# N32H7xx register map
Vendor: Nationstech Ltd.; File version: 1.0
CPU: CM7 r1p1, little endian, MPU, FPU, 4 interrupt priority bits
Registers are 32-bit, read-write, reset 0x0 unless marked. A register's access mark holds for its fields unless they carry their own. Offsets are from the block's base; [hi:lo] are bit positions; {n}, {i} and the like mark numbered series; 'fields as' and 'values as' point back to an identical list.

## MDMA — MDMA controller
Base 0x51102000
0x00 MDMA_ID ro
  [31:0] NBR
0x08 MDMA_VERSION ro reset 0x3230302A
  [31:0] NBR
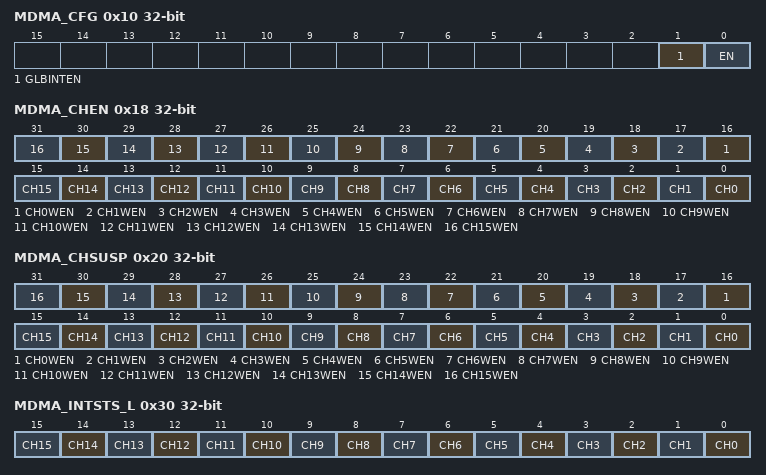
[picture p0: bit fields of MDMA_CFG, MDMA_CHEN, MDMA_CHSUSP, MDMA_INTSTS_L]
0x10 MDMA_CFG
  [1] GLBINTEN, [0] EN
0x18 MDMA_CHEN
  [n+16] CH{n}WEN wo (n=0..15), [n] CH{n} (n=0..15)
0x20 MDMA_CHSUSP
  [n+16] CH{n}WEN wo (n=0..15), [n] CH{n} (n=0..15)
0x30 MDMA_INTSTS_L ro
  [n] CH{n} (n=0..15)
0x34 MDMA_INTSTS_H ro
  [0] COMREG
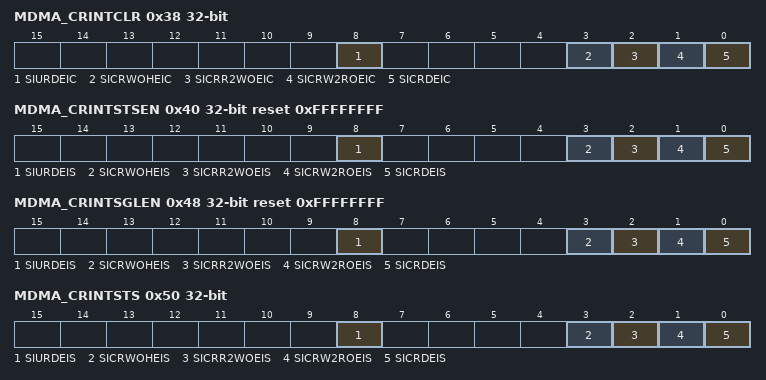
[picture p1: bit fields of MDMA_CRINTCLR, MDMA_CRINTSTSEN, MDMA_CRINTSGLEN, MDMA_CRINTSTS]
0x38 MDMA_CRINTCLR wo
  [8] SIURDEIC, [3] SICRWOHEIC, [2] SICRR2WOEIC, [1] SICRW2ROEIC, [0] SICRDEIC
0x40 MDMA_CRINTSTSEN reset 0xFFFFFFFF
  [8] SIURDEIS, [3] SICRWOHEIS, [2] SICRR2WOEIS, [1] SICRW2ROEIS, [0] SICRDEIS
0x48 MDMA_CRINTSGLEN reset 0xFFFFFFFF
  fields as MDMA_CRINTSTSEN
0x50 MDMA_CRINTSTS ro
  fields as MDMA_CRINTSTSEN
0x58 MDMA_SWRST
  [0] RSTREQ
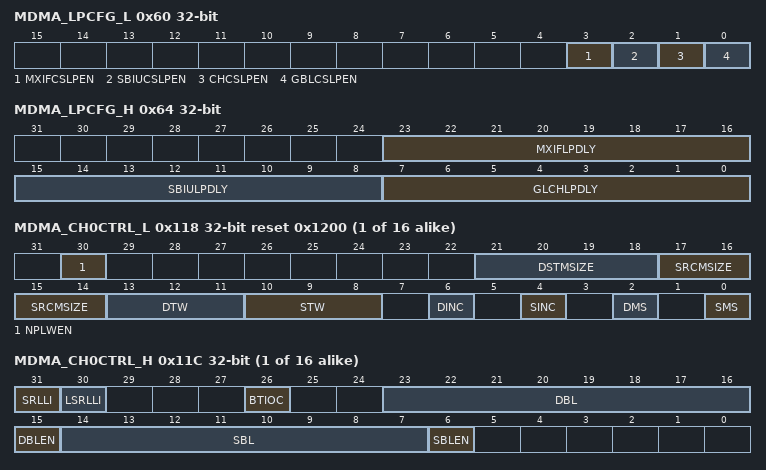
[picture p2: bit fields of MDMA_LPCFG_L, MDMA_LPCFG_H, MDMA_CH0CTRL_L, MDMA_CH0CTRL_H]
0x60 MDMA_LPCFG_L
  [3] MXIFCSLPEN, [2] SBIUCSLPEN, [1] CHCSLPEN, [0] GBLCSLPEN
0x64 MDMA_LPCFG_H
  [23:16] MXIFLPDLY, [15:8] SBIULPDLY, [7:0] GLCHLPDLY
{0x100+0x100*i} MDMA_CH{i}SA_L (i=0..15)
  [31:0] ADDR
{0x104+0x100*i} MDMA_CH{i}SA_H (i=0..15)
  [31:0] ADDR
{0x108+0x100*i} MDMA_CH{i}DA_L (i=0..15)
  [31:0] ADDR
{0x10C+0x100*i} MDMA_CH{i}DA_H (i=0..15)
  [31:0] ADDR
{0x110+0x100*i} MDMA_CH{i}BTS (i=0..15)
  [21:0] NUM
{0x118+0x100*i} MDMA_CH{i}CTRL_L reset 0x1200 (i=0..15)
  [30] NPLWEN, [21:18] DSTMSIZE, [17:14] SRCMSIZE, [13:11] DTW, [10:8] STW, [6] DINC, [4] SINC, [2] DMS, [0] SMS
{0x11C+0x100*i} MDMA_CH{i}CTRL_H (i=0..15)
  [31] SRLLI, [30] LSRLLI, [26] BTIOC, [23:16] DBL, [15] DBLEN, [14:7] SBL, [6] SBLEN
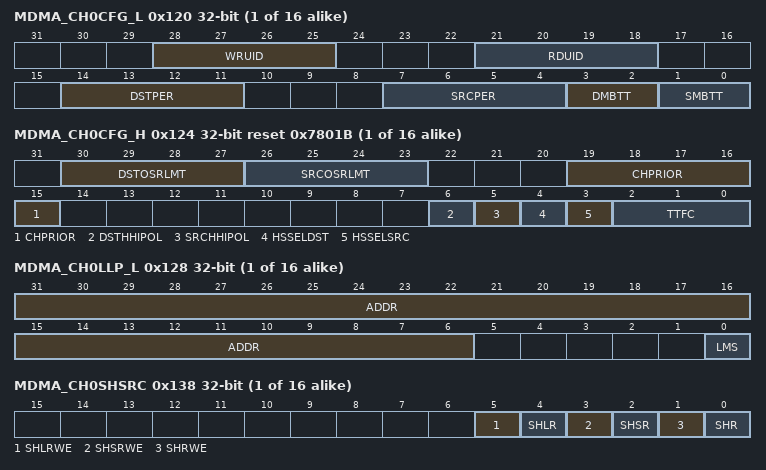
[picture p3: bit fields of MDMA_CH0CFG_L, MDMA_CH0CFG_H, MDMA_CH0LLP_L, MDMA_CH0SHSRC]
{0x120+0x100*i} MDMA_CH{i}CFG_L (i=0..15)
  [28:25] WRUID ro, [21:18] RDUID ro, [14:11] DSTPER, [7:4] SRCPER, [3:2] DMBTT, [1:0] SMBTT
{0x124+0x100*i} MDMA_CH{i}CFG_H reset 0x7801B (i=0..15)
  [30:27] DSTOSRLMT, [26:23] SRCOSRLMT, [19:15] CHPRIOR, [6] DSTHHIPOL ro, [5] SRCHHIPOL ro, [4] HSSELDST, [3] HSSELSRC, [2:0] TTFC
{0x128+0x100*i} MDMA_CH{i}LLP_L (i=0..15)
  [31:6] ADDR, [0] LMS ro
{0x12C+0x100*i} MDMA_CH{i}LLP_H (i=0..15)
  [31:0] ADDR
{0x130+0x100*i} MDMA_CH{i}STS_L ro (i=0..15)
  [21:0] CBTSIZE
{0x134+0x100*i} MDMA_CH{i}STS_H ro (i=0..15)
  [14:0] LEFTDATA
{0x138+0x100*i} MDMA_CH{i}SHSRC (i=0..15)
  [5] SHLRWE wo, [4] SHLR, [3] SHSRWE wo, [2] SHSR, [1] SHRWE wo, [0] SHR
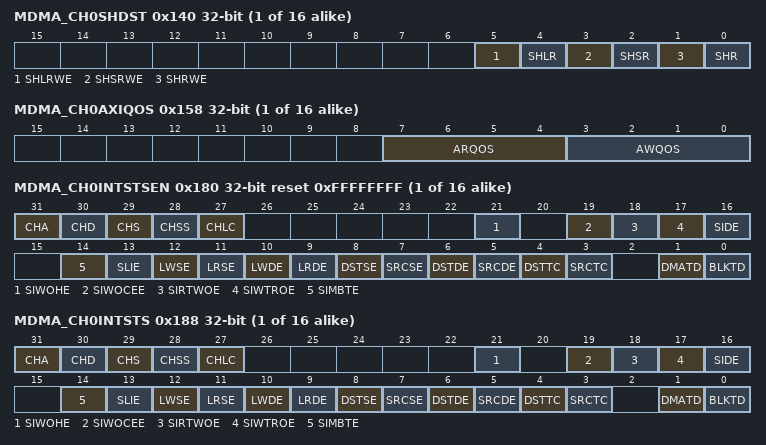
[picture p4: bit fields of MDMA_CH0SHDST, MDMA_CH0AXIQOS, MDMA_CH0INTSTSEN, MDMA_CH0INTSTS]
{0x140+0x100*i} MDMA_CH{i}SHDST (i=0..15)
  fields as MDMA_CH0SHSRC
{0x148+0x100*i} MDMA_CH{i}BTRR wo (i=0..15)
  [0] RESREQ
{0x158+0x100*i} MDMA_CH{i}AXIQOS ro (i=0..15)
  [7:4] ARQOS, [3:0] AWQOS
{0x180+0x100*i} MDMA_CH{i}INTSTSEN reset 0xFFFFFFFF (i=0..15)
  [31] CHA, [30] CHD, [29] CHS, [28] CHSS, [27] CHLC, [21] SIWOHE, [19] SIWOCEE, [18] SIRTWOE, [17] SIWTROE, [16] SIDE, [14] SIMBTE, [13] SLIE, [12] LWSE, [11] LRSE, [10] LWDE, [9] LRDE, [8] DSTSE, [7] SRCSE, [6] DSTDE, [5] SRCDE, [4] DSTTC, [3] SRCTC, [1] DMATD, [0] BLKTD
{0x188+0x100*i} MDMA_CH{i}INTSTS ro (i=0..15)
  fields as MDMA_CH0INTSTSEN
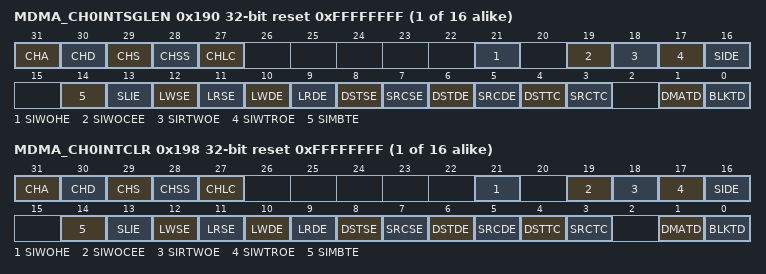
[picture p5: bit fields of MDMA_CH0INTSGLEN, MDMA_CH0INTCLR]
{0x190+0x100*i} MDMA_CH{i}INTSGLEN reset 0xFFFFFFFF (i=0..15)
  fields as MDMA_CH0INTSTSEN
{0x198+0x100*i} MDMA_CH{i}INTCLR wo reset 0xFFFFFFFF (i=0..15)
  fields as MDMA_CH0INTSTSEN

## SDRAM — Synchronous dynamic random access memory controller
Base 0x51106000
0x80 SDRAM_BADD1 — Base Address for SDRAM1 Register
  [31:12] ADDBASE
0x84 SDRAM_ADDMASK1 — Address Mask for SDRAM1 Register
  [31:12] ADDMASK
0x88 SDRAM_BADD2 — Base Address for SDRAM2 Register
  [31:12] ADDBASE
0x8C SDRAM_ADDMASK2 — Address Mask for SDRAM2 Register
  [31:12] ADDMASK
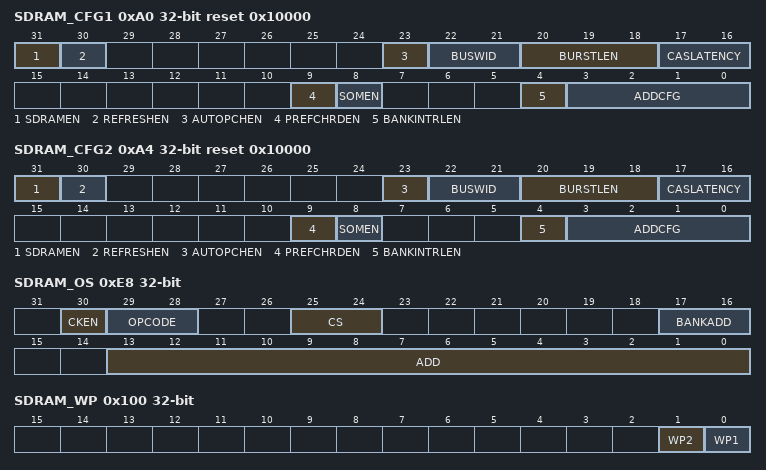
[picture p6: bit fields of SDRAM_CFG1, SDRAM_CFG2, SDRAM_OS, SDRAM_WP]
0xA0 SDRAM_CFG1 reset 0x10000 — SDRAM1 Configuration Register
  [31] SDRAMEN, [30] REFRESHEN, [23] AUTOPCHEN, [22:21] BUSWID, [20:18] BURSTLEN, [17:16] CASLATENCY, [9] PREFCHRDEN, [8] SOMEN, [4] BANKINTRLEN, [3:0] ADDCFG
0xA4 SDRAM_CFG2 reset 0x10000 — SDRAM2 Configuration Register
  fields as SDRAM_CFG1
0xB0 SDRAM_RAT — Row Active Time Register
  [5:0] TRAS
0xB4 SDRAM_RCT — Row Cycle Time Register
  [5:0] TRC
0xB8 SDRAM_RRDLY — Row Active to Row Active Delay Register
  [5:0] TRRD
0xBC SDRAM_PT — Precharge Time Register
  [5:0] TRP
0xC0 SDRAM_WRT — Write Recovery Time Register
  [5:0] TWR
0xC4 SDRAM_RFCT — Refresh Cycle Time Register
  [5:0] TRFC
0xC8 SDRAM_RCDLY — RAS to CAS Delay Register
  [3:0] TRCD
0xCC SDRAM_RI — Refresh Interval Register
  [23:0] TRI
0xE0 SDRAM_CBO — Synchronous Memory Buffer Operation Register
  [31:0] DUMMY
0xE4 SDRAM_OR — SDRAM Operation Request Register
  [31:0] DUMMY
0xE8 SDRAM_OS — SDRAM Operation Setup Register
  [30] CKEN, [29:28] OPCODE, [25:24] CS, [17:16] BANKADD, [13:0] ADD
0x100 SDRAM_WP — Write Protection Register
  [1] WP2, [0] WP1
